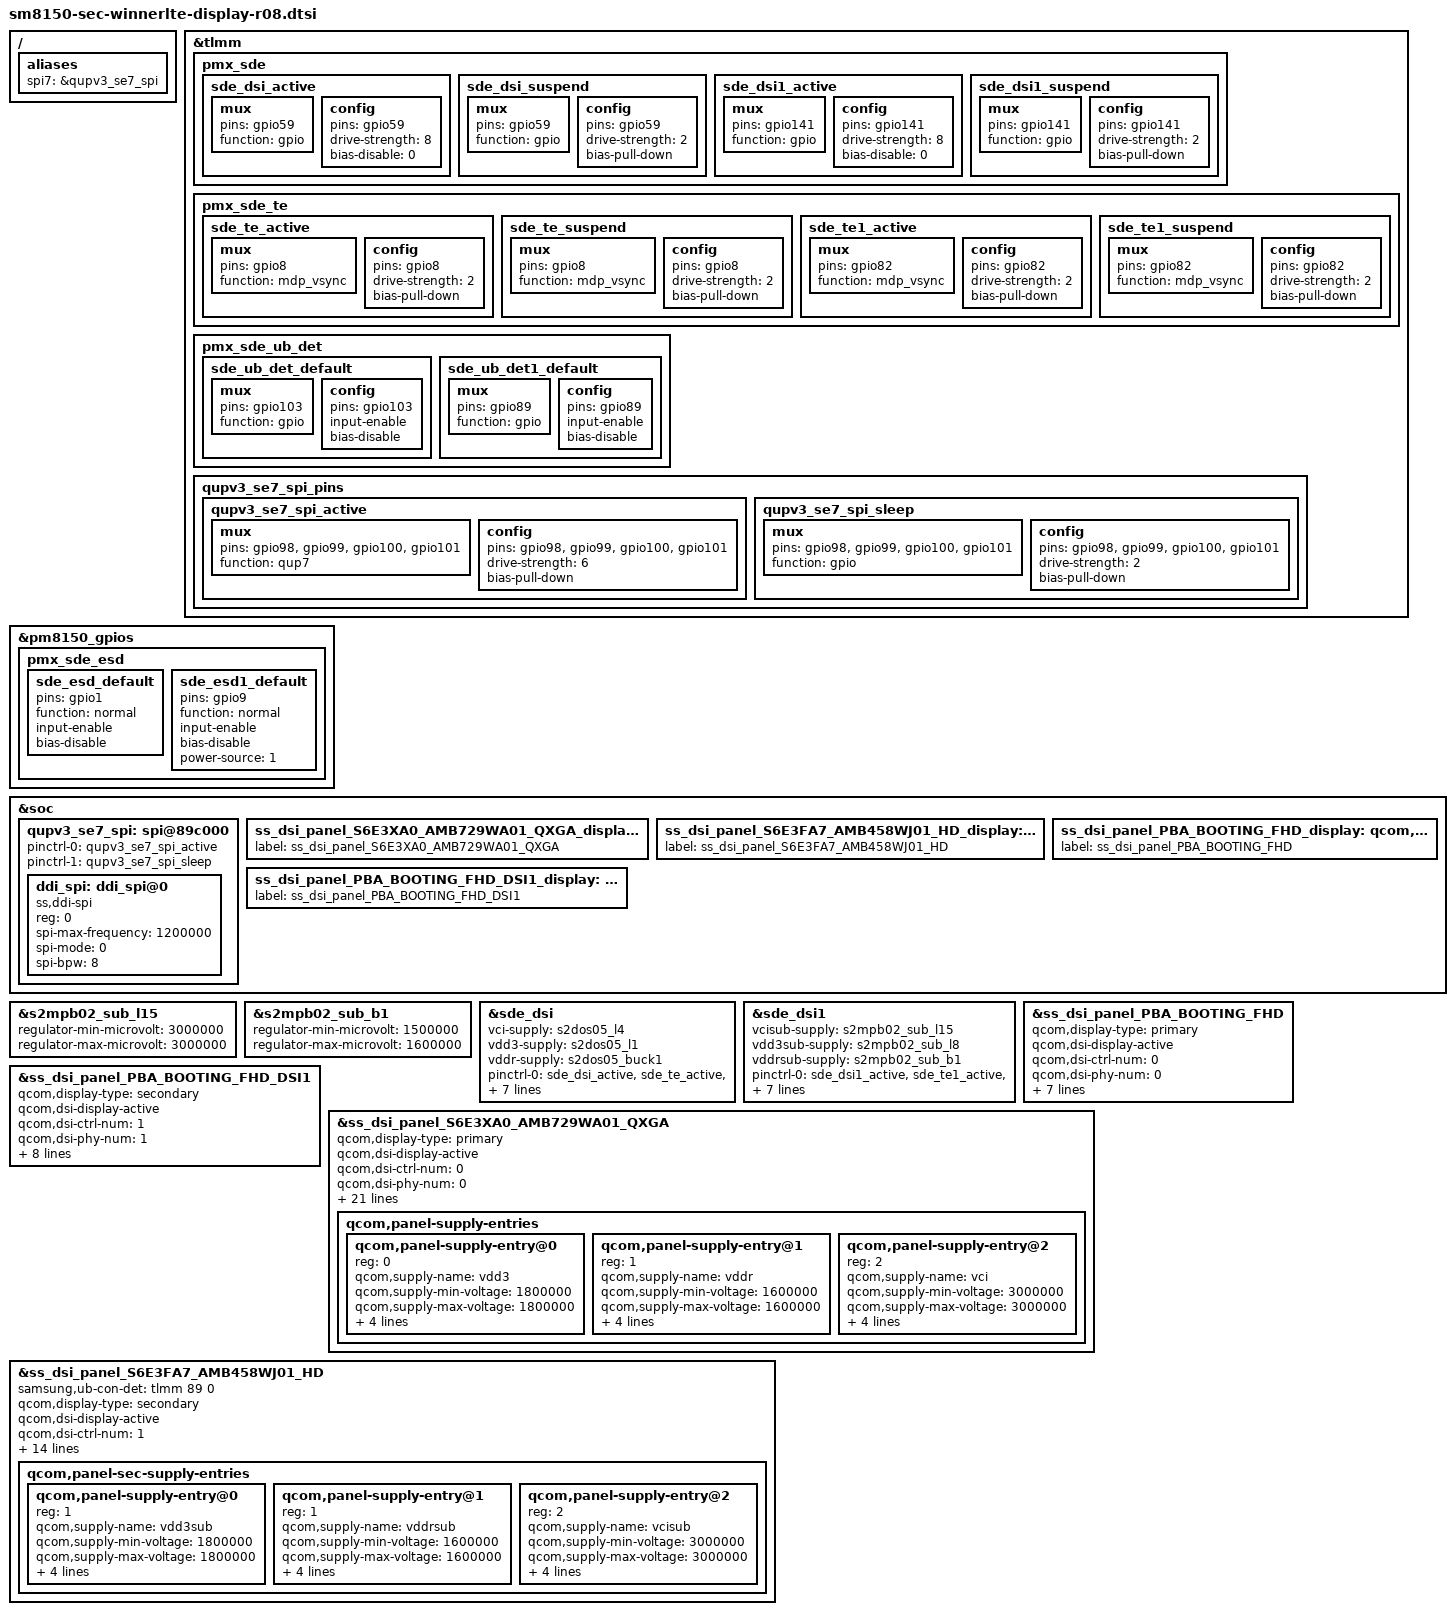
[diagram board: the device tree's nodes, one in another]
/* Copyright (c) 2016-2017, The Linux Foundation. All rights reserved.
 *
 * This program is free software; you can redistribute it and/or modify
 * it under the terms of the GNU General Public License version 2 and
 * only version 2 as published by the Free Software Foundation.
 *
 * This program is distributed in the hope that it will be useful,
 * but WITHOUT ANY WARRANTY; without even the implied warranty of
 * MERCHANTABILITY or FITNESS FOR A PARTICULAR PURPOSE.  See the
 * GNU General Public License for more details.
 */

#include "../../../../../drivers/gpu/drm/msm/samsung/SELF_DISPLAY/self_display_cmd_XA0.dtsi"
#include "../../../../../drivers/gpu/drm/msm/samsung/S6E3XA0_AMB729WA01/dsi_panel_S6E3XA0_AMB729WA01_qxga_octa_cmd.dtsi"
#include "../../../../../drivers/gpu/drm/msm/samsung/SELF_DISPLAY/self_display_cmd_FA7_AMB458WJ01.dtsi"
#include "../../../../../drivers/gpu/drm/msm/samsung/S6E3FA7_AMB458WJ01/dsi_panel_S6E3FA7_AMB458WJ01_hd_octa_cmd.dtsi"
#include "../../../../../drivers/gpu/drm/msm/samsung/PBA_BOOTING/dsi_panel_PBA_BOOTING_fhd_video.dtsi"
#include "../../../../../drivers/gpu/drm/msm/samsung/PBA_BOOTING_DSI1/dsi_panel_PBA_BOOTING_fhd_video_dsi1.dtsi"

/{
	aliases {
		spi7 = &qupv3_se7_spi;
	};
};

&tlmm {
	pmx_sde: pmx_sde {
		sde_dsi_active: sde_dsi_active {
			mux {
				pins = "gpio59";
				function = "gpio";
			};

			config {
				pins = "gpio59";
				drive-strength = <8>;   /* 8 mA */
				bias-disable = <0>;   /* no pull */
			};
		};
		sde_dsi_suspend: sde_dsi_suspend {
			mux {
				pins = "gpio59";
				function = "gpio";
			};

			config {
				pins = "gpio59";
				drive-strength = <2>;   /* 2 mA */
				bias-pull-down;         /* PULL DOWN */
			};
		};

		sde_dsi1_active: sde_dsi1_active {
			mux {
				pins = "gpio141";
				function = "gpio";
			};

			config {
				pins = "gpio141";
				drive-strength = <8>;   /* 8 mA */
				bias-disable = <0>;   /* no pull */
			};
		};
		sde_dsi1_suspend: sde_dsi1_suspend {
			mux {
				pins = "gpio141";
				function = "gpio";
			};

			config {
				pins = "gpio141";
				drive-strength = <2>;   /* 2 mA */
				bias-pull-down;         /* PULL DOWN */
			};
		};
	};
	pmx_sde_te {
		sde_te_active: sde_te_active {
			mux {
				pins = "gpio8";
				function = "mdp_vsync";
			};

			config {
				pins = "gpio8";
				drive-strength = <2>;   /* 2 mA */
				bias-pull-down;         /* PULL DOWN */
			};
		};

		sde_te_suspend: sde_te_suspend {
			mux {
				pins = "gpio8";
				function = "mdp_vsync";
			};

			config {
				pins = "gpio8";
				drive-strength = <2>;   /* 2 mA */
				bias-pull-down;         /* PULL DOWN */
			};
		};

		sde_te1_active: sde_te1_active {
			mux {
				pins = "gpio82";
				function = "mdp_vsync";
			};

			config {
				pins = "gpio82";
				drive-strength = <2>;   /* 2 mA */
				bias-pull-down;         /* PULL DOWN */
			};
		};

		sde_te1_suspend: sde_te1_suspend {
			mux {
				pins = "gpio82";
				function = "mdp_vsync";
			};

			config {
				pins = "gpio82";
				drive-strength = <2>;   /* 2 mA */
				bias-pull-down;         /* PULL DOWN */
			};
		};

	};
	pmx_sde_ub_det {
		sde_ub_det_default: sde_ub_det_default {
			mux {
				pins = "gpio103";
				function = "gpio";
			};
			config {
				pins = "gpio103";
				input-enable;
				bias-disable;
			};
		};

		sde_ub_det1_default: sde_ub_det1_default {
			mux {
				pins = "gpio89";
				function = "gpio";
			};
			config {
				pins = "gpio89";
				input-enable;
				bias-disable;
			};
		};
	};
	qupv3_se7_spi_pins: qupv3_se7_spi_pins {
		qupv3_se7_spi_active: qupv3_se7_spi_active {
			mux {
				pins = "gpio98", "gpio99", "gpio100",
							"gpio101";
				function = "qup7";
			};

			config {
				pins = "gpio98", "gpio99", "gpio100",
							"gpio101";
				drive-strength = <6>;
				bias-pull-down; /* prevent MISO floating */
			};
		};

		qupv3_se7_spi_sleep: qupv3_se7_spi_sleep {
			mux {
				pins = "gpio98", "gpio99", "gpio100",
							"gpio101";
				function = "gpio";
			};

			config {
				pins = "gpio98", "gpio99", "gpio100",
							"gpio101";
				drive-strength = <2>;
				bias-pull-down;
			};
		};
	};
};

&pm8150_gpios {
	pmx_sde_esd {
		sde_esd_default: sde_esd_default {
			pins = "gpio1";
			function = "normal";
			input-enable;
			bias-disable;
		};

		sde_esd1_default: sde_esd1_default {
			pins = "gpio9";
			function = "normal";
			input-enable;
			bias-disable;
			power-source = <1>;
		};
	};
};

&soc {
	qupv3_se7_spi: spi@89c000 {
		status = "ok";

		pinctrl-0 = <&qupv3_se7_spi_active>;
		pinctrl-1 = <&qupv3_se7_spi_sleep>;

		ddi_spi:ddi_spi@0  {	// LCD_SPI
			compatible = "ss,ddi-spi";
			reg = <0>;
			spi-max-frequency = <1200000>;
			spi-mode = <0>;
			spi-bpw = <8>;
		};
	};
};

&soc {
	/* winner main panel */
	ss_dsi_panel_S6E3XA0_AMB729WA01_QXGA_display: qcom,dsi-display@17 {
		label = "ss_dsi_panel_S6E3XA0_AMB729WA01_QXGA";
	};

	/* astar panel */
	ss_dsi_panel_S6E3FA7_AMB458WJ01_HD_display: qcom,dsi-display@18 {
		label = "ss_dsi_panel_S6E3FA7_AMB458WJ01_HD";
	};

	/* PBA */
	ss_dsi_panel_PBA_BOOTING_FHD_display: qcom,dsi-display@19 {
		label = "ss_dsi_panel_PBA_BOOTING_FHD";
	};

	/* PBA for secondary display (DSI1) */
	ss_dsi_panel_PBA_BOOTING_FHD_DSI1_display: qcom,dsi-display@20 {
		label = "ss_dsi_panel_PBA_BOOTING_FHD_DSI1";
	};
};

/* override voltage limitation for display LDO */
&s2mpb02_sub_l15 {	/* VDD_SUB_DDI_3P0 */
	regulator-min-microvolt = <3000000>;
	regulator-max-microvolt = <3000000>;
};

&s2mpb02_sub_b1 {	/* VDD_SUB_DDR_1P6 */
	regulator-min-microvolt = <1500000>;
	regulator-max-microvolt = <1600000>;
	/delete-property/ regulator-always-on;
};

&sde_dsi {
	vci-supply = <&s2dos05_l4>;	/* VDD_MAIN_DDI_3P0, S2DOS05 LDO4 */
	vdd3-supply = <&s2dos05_l1>;	/* VDD_MAIN_DDI_1P8, S2DOS05 LDO1 */
	vddr-supply = <&s2dos05_buck1>;	/* VDD_MAIN_DDR_1P6, S2DOS05 buck */

	pinctrl-names = "panel_active", "panel_suspend";
	pinctrl-0 = <&sde_dsi_active &sde_te_active &sde_ub_det_default &sde_esd_default>;
	pinctrl-1 = <&sde_dsi_suspend &sde_te_suspend &sde_ub_det_default &sde_esd_default>;

	qcom,platform-te-gpio = <&tlmm 8 0>;

	qcom,dsi-display-list =
		<&ss_dsi_panel_S6E3XA0_AMB729WA01_QXGA
		&ss_dsi_panel_PBA_BOOTING_FHD>;
};

/* override display-list / supply for samsung panel */
&sde_dsi1 {
	vcisub-supply = <&s2mpb02_sub_l15>; /* VDD_SUB_DDI_3P0, S2MPB02 VLDO15 */
	vdd3sub-supply = <&s2mpb02_sub_l8>; /* VDD_SUB_DDI_1P8, S2MPB02 VLDO8 */
	vddrsub-supply = <&s2mpb02_sub_b1>; /* VDD_SUB_DDR_1P6, S2MPB02 buck1 */

	pinctrl-names = "panel_active", "panel_suspend";
	pinctrl-0 = <&sde_dsi1_active &sde_te1_active &sde_ub_det1_default &sde_esd1_default>;
	pinctrl-1 = <&sde_dsi1_suspend &sde_te1_suspend &sde_ub_det1_default  &sde_esd1_default>;

	qcom,platform-te-gpio = <&tlmm 82 0>;

	qcom,dsi-display-list =
		<&ss_dsi_panel_S6E3FA7_AMB458WJ01_HD
		&ss_dsi_panel_PBA_BOOTING_FHD_DSI1>;
};

&ss_dsi_panel_PBA_BOOTING_FHD {
	qcom,display-type = "primary";
	qcom,dsi-display-active;

	qcom,dsi-ctrl-num = <0>;
	qcom,dsi-phy-num = <0>;
	qcom,dsi-select-clocks = "mux_byte_clk0", "mux_pixel_clk0";

	qcom,dsi-panel = <&ss_dsi_panel_PBA_BOOTING_FHD>;

	qcom,platform-reset-gpio = <&tlmm 59 0>;
	qcom,platform-te-source = <0>;
	samsung,ub-con-det = <&tlmm 103 0>;
	/* In pba booting mode, SS disables continuous splash mode.
	 * But QC recommended to enable splash mode as default..
	 * In case of splash enabled, it should not touch has_src_split  setitng..
	 * Refer to case 03756419.
	 */
	samsung,enable_splash_pba; /* enable continuous spalsh on PBA mode.. */
};

&ss_dsi_panel_PBA_BOOTING_FHD_DSI1 {
	qcom,display-type = "secondary";
	qcom,dsi-display-active;

	qcom,dsi-ctrl-num = <1>;
	qcom,dsi-phy-num = <1>;
	qcom,dsi-select-clocks = "mux_byte_clk1", "mux_pixel_clk1";

	qcom,dsi-panel = <&ss_dsi_panel_PBA_BOOTING_FHD_DSI1>;

	qcom,platform-sec-reset-gpio = <&tlmm 141 0>;
	qcom,platform-te-source = <1>;
	samsung,ub-con-det = <&tlmm 89 0>; // SUB_DISP_CON_DET GPIO 89
	/* In pba booting mode, SS disables continuous splash mode.
	 * But QC recommended to enable splash mode as default..
	 * In case of splash enabled, it should not touch has_src_split  setitng..
	 * Refer to case 03756419.
	 */
	samsung,enable_splash_pba; /* enable continuous spalsh on PBA mode.. */
};

&ss_dsi_panel_S6E3XA0_AMB729WA01_QXGA {
	qcom,display-type = "primary";
	qcom,dsi-display-active;

	qcom,dsi-ctrl-num = <0>;
	qcom,dsi-phy-num = <0>;
	qcom,dsi-select-clocks = "mux_byte_clk0", "mux_pixel_clk0";

	qcom,dsi-panel = <&ss_dsi_panel_S6E3XA0_AMB729WA01_QXGA>;

	qcom,platform-reset-gpio = <&tlmm 59 0>;
	qcom,platform-te-source = <0>;

	/delete-property/ qcom,panel-mode-gpio;

	qcom,panel-supply-entries {
		#address-cells = <1>;
		#size-cells = <0>;

		qcom,panel-supply-entry@0 {
		    reg = <0>;
		    qcom,supply-name = "vdd3";
		    qcom,supply-min-voltage = <1800000>;
		    qcom,supply-max-voltage = <1800000>;
		    qcom,supply-enable-load = <100000>;
		    qcom,supply-disable-load = <100>;
		    qcom,supply-pre-on-sleep = <0>; /* unit is ms*/
		    qcom,supply-post-on-sleep = <0>;
		};

		qcom,panel-supply-entry@1 {
		    reg = <1>;
		    qcom,supply-name = "vddr";
		    qcom,supply-min-voltage = <1600000>;
		    qcom,supply-max-voltage = <1600000>;
		    qcom,supply-enable-load = <100000>;
		    qcom,supply-disable-load = <100>;
		    qcom,supply-pre-on-sleep = <0>; /* unit is ms*/
		    qcom,supply-post-on-sleep = <0>;
		};

		qcom,panel-supply-entry@2 {
		    reg = <2>;
		    qcom,supply-name = "vci";
		    qcom,supply-min-voltage = <3000000>;
		    qcom,supply-max-voltage = <3000000>;
		    qcom,supply-enable-load = <100000>;
		    qcom,supply-disable-load = <100>;
		    qcom,supply-pre-on-sleep = <0>; /* unit is ms*/
		    qcom,supply-post-on-sleep = <12>;
		};
	};
};

&ss_dsi_panel_S6E3XA0_AMB729WA01_QXGA {
	samsung,esd-irq-gpio1 = <&pm8150_gpios 1 0>; // MAIN_DISP_DET
	samsung,ub-con-det = <&tlmm 103 0>;
	samsung,delayed-display-on = <1>;

	samsung,lpm-power-control;
	samsung,lpm-power-control-supply-name = "vddr";
	samsung,lpm-power-control-supply-min-voltage = <1500000>;
	samsung,lpm-power-control-supply-max-voltage = <1500000>;
	samsung,lpm-power-control-elvss-name = "s2dos05-elvss";
	samsung,lpm-power-control-elvss-lpm-voltage = <2000>;
	samsung,lpm-power-control-elvss-normal-voltage = <8000>;
};


&ss_dsi_panel_S6E3FA7_AMB458WJ01_HD {
	samsung,ub-con-det = <&tlmm 89 0>; // SUB_DISP_CON_DET GPIO 89

	qcom,display-type = "secondary";
	qcom,dsi-display-active;

	qcom,dsi-ctrl-num = <1>;
	qcom,dsi-phy-num = <1>;
	qcom,dsi-select-clocks = "mux_byte_clk1", "mux_pixel_clk1";

	qcom,dsi-panel = <&ss_dsi_panel_S6E3FA7_AMB458WJ01_HD>;

	qcom,platform-sec-reset-gpio = <&tlmm 141 0>;
	qcom,platform-te-source = <1>;
	samsung,esd-irq-gpio1 = <&pm8150_gpios 9 0>; // SUB_DISP_DET

	/delete-property/ qcom,panel-mode-gpio;

	qcom,panel-sec-supply-entries {
		#address-cells = <1>;
		#size-cells = <0>;

		qcom,panel-supply-entry@0 {
		    reg = <1>;
		    qcom,supply-name = "vdd3sub";
		    qcom,supply-min-voltage = <1800000>;
		    qcom,supply-max-voltage = <1800000>;
		    qcom,supply-enable-load = <100000>;
		    qcom,supply-disable-load = <100>;
		    qcom,supply-pre-on-sleep = <0>; /* unit is ms*/
		    qcom,supply-post-on-sleep = <0>;
		};

		qcom,panel-supply-entry@1 {
		    reg = <1>;
		    qcom,supply-name = "vddrsub";
		    qcom,supply-min-voltage = <1600000>;
		    qcom,supply-max-voltage = <1600000>;
		    qcom,supply-enable-load = <100000>;
		    qcom,supply-disable-load = <100>;
		    qcom,supply-pre-on-sleep = <0>; /* unit is ms*/
		    qcom,supply-post-on-sleep = <0>;
		};

		qcom,panel-supply-entry@2 {
		    reg = <2>;
		    qcom,supply-name = "vcisub";
		    qcom,supply-min-voltage = <3000000>;
		    qcom,supply-max-voltage = <3000000>;
		    qcom,supply-enable-load = <100000>;
		    qcom,supply-disable-load = <100>;
		    qcom,supply-pre-on-sleep = <0>; /* unit is ms*/
		    qcom,supply-post-on-sleep = <10>;
		};
	};
};

&ss_dsi_panel_S6E3FA7_AMB458WJ01_HD {
	samsung,lpm-power-control;
	samsung,lpm-power-control-supply-name = "vddrsub";
	samsung,lpm-power-control-supply-min-voltage = <1500000>;
	samsung,lpm-power-control-supply-max-voltage = <1500000>;
};
